# trng_revc_me13 register map
Registers are access not given, no defined reset value unless marked. A register's access mark holds for its fields unless they carry their own. Offsets are from the block's base; lines under a group give offsets from that group; [hi:lo] are bit positions; {n}, {i} and the like mark numbered series; 'fields as' and 'values as' point back to an identical list; <NAME> marks a mode.

## Memory map
0x4004D000 TRNG size 0x1000 — Random Number Generator.

## Interrupts
4 TRNG — TRNG interrupt.

## TRNG — Random Number Generator.
Base 0x4004D000
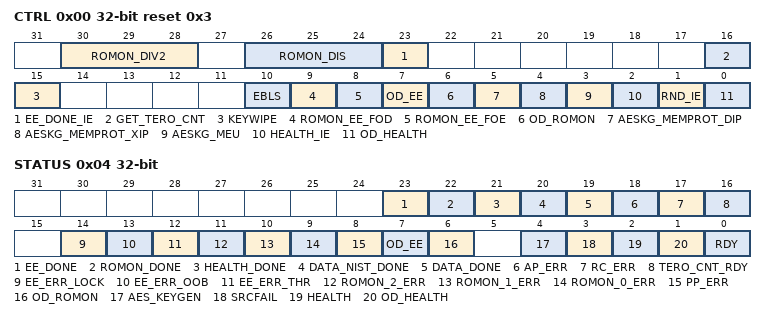
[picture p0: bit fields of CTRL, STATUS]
0x00 CTRL reset 0x3 — TRNG Control Register.
  [30:28] ROMON_DIV2 — Divide ring by 2.
    0=RO_0 (Ring Oscillator 0.); 1=RO_1 (Ring Oscillator 1.); 2=RO_2 (Ring Oscillator 2.)
  [26:24] ROMON_DIS — Ring Oscillator Disable.
    1=RO_0 (Ring Oscillator 0.); 2=RO_1 (Ring Oscillator 1.); 4=RO_2 (Ring Oscillator 2.)
  [23] EE_DONE_IE — Entropy Estimator Done Interrupt Enable.
  [16] GET_TERO_CNT — Get Tero Count.
  [15] KEYWIPE — To wipe the Battery Backed key.
  [10] EBLS — Entropy Bit Load Select.
  [9] ROMON_EE_FOD — Ring Oscillator Monitors and Entropy Estimator Freeze on Done.
  [8] ROMON_EE_FOE — Ring Oscillator Monitors and Entropy Estimator Freeze on Error.
  [7] OD_EE — Start entropy estimator on demand test.
  [6] OD_ROMON — Start ring oscillator monitor on demand test.
  [5] AESKG_MEMPROT_DIP — Generate and transfer 128 bit MEMPROT_DIP key to AES key storage.
  [4] AESKG_MEMPROT_XIP — Generate and transfer 128 bit MEMPROT_XIP key to AES key storage.
  [3] AESKG_MEU — Generate and transfer 256 bit MEU key to AES Key storage.
  [2] HEALTH_IE — Enable IRQ generation when a health test fails.
  [1] RND_IE — To enable IRQ generation when a new 32-bit Random number is ready.
    0=disable; 1=enable
  [0] OD_HEALTH — Start On-Demand health test.
0x04 STATUS — Data. The content of this register is valid only when RNG_IS = 1. When TRNG is disabled, read returns 0x0000 0000.
  [23] EE_DONE — Entropy Estimator Test Done.
  [22] ROMON_DONE — Ring Oscillator Monitor Test Done.
  [21] HEALTH_DONE — Health Test Done.
  [20] DATA_NIST_DONE — Data NIST register has been loaded with at least 32 new entropy bits.
  [19] DATA_DONE — Data register has been loaded with at least 32 new entropy bits.
  [18] AP_ERR — Adaptive Proportion Error.
  [17] RC_ERR — Repetition Count Error.
  [16] TERO_CNT_RDY — TERO Count Ready.
  [14] EE_ERR_LOCK — Entropy Estimator Lock Error.
  [13] EE_ERR_OOB — Entropy Estimator Out of Bounds Error..
  [12] EE_ERR_THR — Entropy Estimator Threshold Error.
  [11] ROMON_2_ERR — Ring Oscillator 2 Monitor Error.
  [10] ROMON_1_ERR — Ring Oscillator 1 Monitor Error.
  [9] ROMON_0_ERR — Ring Oscillator 0 Monitor Error.
  [8] PP_ERR — Post process error.
  [7] OD_EE — On demand entropy estimator status.
  [6] OD_ROMON — On demand ring oscillator test status.
  [4] AES_KEYGEN — AESKGD.
  [3] SRCFAIL — Entropy source has failed.
  [2] HEALTH — Health test status.
  [1] OD_HEALTH — On-Demand health test status.
  [0] RDY — 32-bit random data is ready to read from TRNG_DATA register. Reading TRNG_DATA when RND_RDY=0 will return all 0's. IRQ is generated when RND_RDY=1 if TRNG_CN.RND_IRQ_EN=1.
    0=Busy (TRNG Busy); 1=Ready (32 bit random data is ready)
0x08 DATA ro — Data. The content of this register is valid only when RNG_IS = 1. When TRNG is disabled, read returns 0x0000 0000.
  [31:0] DATA — Data. The content of this register is valid only when RNG_IS =1. When TNRG is disabled, read returns 0x0000 0000.
0x38 DATA_NIST
  [31:0] DATA — Ring Oscillator 1 Monitor Last Ring Oscillator Count.
